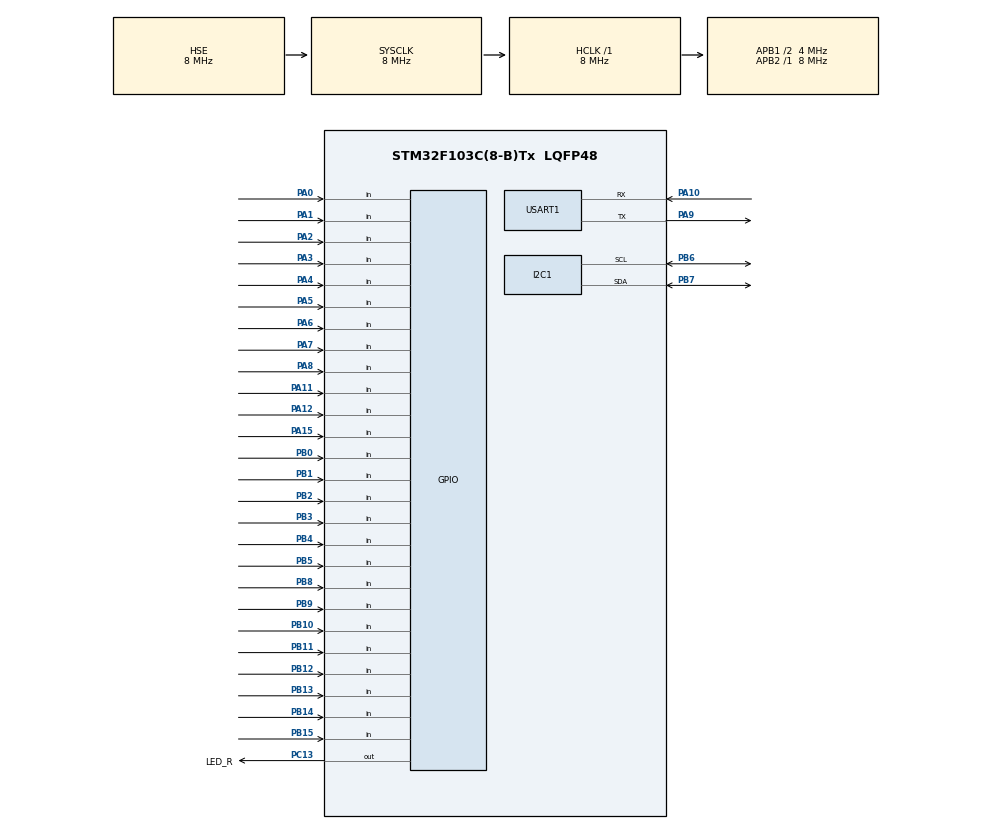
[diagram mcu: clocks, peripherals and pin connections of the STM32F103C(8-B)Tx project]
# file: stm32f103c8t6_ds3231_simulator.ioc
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I2C1.OwnAddress=0x68
IWDG.Prescaler=IWDG_PRESCALER_256
Mcu.Family=STM32F1
Mcu.Name=STM32F103C(8-B)Tx
Mcu.Package=LQFP48
NVIC.I2C1_ER_IRQn=true\:0\:0\:false\:false\:true\:true\:true\:true
NVIC.I2C1_EV_IRQn=true\:0\:0\:false\:false\:true\:true\:true\:true
NVIC.PriorityGroup=NVIC_PRIORITYGROUP_4
NVIC.RTC_IRQn=true\:0\:0\:false\:false\:true\:true\:true\:true
NVIC.USART1_IRQn=true\:0\:0\:false\:false\:true\:true\:true\:true
PA0-WKUP.GPIO_PuPd=GPIO_PULLUP
PA0-WKUP.Signal=GPIO_Input
PA1.GPIO_PuPd=GPIO_PULLUP
PA1.Signal=GPIO_Input
PA10.Mode=Asynchronous
PA10.Signal=USART1_RX
PA11.GPIO_PuPd=GPIO_PULLUP
PA11.Signal=GPIO_Input
PA12.GPIO_PuPd=GPIO_PULLUP
PA12.Signal=GPIO_Input
PA13.Mode=Serial_Wire
PA13.Signal=SYS_JTMS-SWDIO
PA14.Mode=Serial_Wire
PA14.Signal=SYS_JTCK-SWCLK
PA15.GPIO_PuPd=GPIO_PULLUP
PA15.Signal=GPIO_Input
PA2.GPIO_PuPd=GPIO_PULLUP
PA2.Signal=GPIO_Input
PA3.GPIO_PuPd=GPIO_PULLUP
PA3.Signal=GPIO_Input
PA4.GPIO_PuPd=GPIO_PULLUP
PA4.Signal=GPIO_Input
PA5.GPIO_PuPd=GPIO_PULLUP
PA5.Signal=GPIO_Input
PA6.GPIO_PuPd=GPIO_PULLUP
PA6.Signal=GPIO_Input
PA7.GPIO_PuPd=GPIO_PULLUP
PA7.Signal=GPIO_Input
PA8.GPIO_PuPd=GPIO_PULLUP
PA8.Signal=GPIO_Input
PA9.Mode=Asynchronous
PA9.Signal=USART1_TX
PB0.GPIO_PuPd=GPIO_PULLUP
PB0.Signal=GPIO_Input
PB1.GPIO_PuPd=GPIO_PULLUP
PB1.Signal=GPIO_Input
PB10.GPIO_PuPd=GPIO_PULLUP
PB10.Signal=GPIO_Input
PB11.GPIO_PuPd=GPIO_PULLUP
PB11.Signal=GPIO_Input
PB12.GPIO_PuPd=GPIO_PULLUP
PB12.Signal=GPIO_Input
PB13.GPIO_PuPd=GPIO_PULLUP
PB13.Signal=GPIO_Input
PB14.GPIO_PuPd=GPIO_PULLUP
PB14.Signal=GPIO_Input
PB15.GPIO_PuPd=GPIO_PULLUP
PB15.Signal=GPIO_Input
PB2.GPIO_PuPd=GPIO_PULLUP
PB2.Signal=GPIO_Input
PB3.GPIO_PuPd=GPIO_PULLUP
PB3.Signal=GPIO_Input
PB4.GPIO_PuPd=GPIO_PULLUP
PB4.Signal=GPIO_Input
PB5.GPIO_PuPd=GPIO_PULLUP
PB5.Signal=GPIO_Input
PB6.Mode=I2C
PB6.Signal=I2C1_SCL
PB7.Mode=I2C
PB7.Signal=I2C1_SDA
PB8.GPIO_PuPd=GPIO_PULLUP
PB8.Signal=GPIO_Input
PB9.GPIO_PuPd=GPIO_PULLUP
PB9.Signal=GPIO_Input
PC13-TAMPER-RTC.GPIO_Label=LED_R
PC13-TAMPER-RTC.GPIO_PuPd=GPIO_PULLUP
PC13-TAMPER-RTC.GPIO_Speed=GPIO_SPEED_FREQ_HIGH
PC13-TAMPER-RTC.PinState=GPIO_PIN_SET
PC13-TAMPER-RTC.Signal=GPIO_Output
PC14-OSC32_IN.Mode=LSE-External-Oscillator
PC14-OSC32_IN.Signal=RCC_OSC32_IN
PC15-OSC32_OUT.Mode=LSE-External-Oscillator
PC15-OSC32_OUT.Signal=RCC_OSC32_OUT
PD0-OSC_IN.Mode=HSE-External-Oscillator
PD0-OSC_IN.Signal=RCC_OSC_IN
PD1-OSC_OUT.Mode=HSE-External-Oscillator
PD1-OSC_OUT.Signal=RCC_OSC_OUT
ProjectManager.HeapSize=0x200
ProjectManager.StackSize=0x400
ProjectManager.TargetToolchain=MDK-ARM V5
RCC.AHBFreq_Value=8000000
RCC.APB1CLKDivider=RCC_HCLK_DIV2
RCC.APB1Freq_Value=4000000
RCC.APB1TimFreq_Value=8000000
RCC.APB2Freq_Value=8000000
RCC.APB2TimFreq_Value=8000000
RCC.HCLKFreq_Value=8000000
RCC.PLLMUL=RCC_PLL_MUL9
RCC.PLLSourceVirtual=RCC_PLLSOURCE_HSE
RCC.SYSCLKFreq_VALUE=8000000
RCC.SYSCLKSource=RCC_SYSCLKSOURCE_HSE
RCC.USBFreq_Value=48000000
RCC.USBPrescaler=RCC_USBCLKSOURCE_PLL_DIV1_5
RCC.VDD_VALUE=3
USART1.VirtualMode=VM_ASYNC
VP_IWDG_VS_IWDG.Mode=IWDG_Activate
VP_RTC_No_RTC_Output.Mode=RTC_OUT_NO
VP_RTC_VS_RTC_Activate.Mode=RTC_Enabled
VP_RTC_VS_RTC_Calendar.Mode=RTC_Calendar
board=custom

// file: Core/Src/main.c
/* USER CODE BEGIN Header */
/**
  ******************************************************************************
  * @file           : main.c
  * @brief          : Main program body
  ******************************************************************************
  * @attention
  *
  * Copyright (c) 2026 STMicroelectronics.
  * All rights reserved.
  *
  * This software is licensed under terms that can be found in the LICENSE file
  * in the root directory of this software component.
  * If no LICENSE file comes with this software, it is provided AS-IS.
  *
  ******************************************************************************
  */
/* USER CODE END Header */
#include "main.h"
#include "i2c.h"
#include "iwdg.h"
#include "rtc.h"
#include "usart.h"
#include "gpio.h"

/* USER CODE BEGIN Includes */
#include "ds3231_sim.h"
#include "Delay.h"
/* USER CODE END Includes */

void SystemClock_Config(void);

int main(void)
{

  /* MCU Configuration--------------------------------------------------------*/

  /* Reset of all peripherals, Initializes the Flash interface and the Systick. */
  HAL_Init();

  /* Configure the system clock */
  SystemClock_Config();

  /* Initialize all configured peripherals */
  MX_GPIO_Init();
  MX_I2C1_Init();
  MX_RTC_Init();
  MX_USART1_UART_Init();
  MX_IWDG_Init();
  /* USER CODE BEGIN 2 */
  ds3231_sim_init();   /* I2C1 从机 0x68 模拟 DS3231（RTC 日历由 MX_RTC_Init 初始化） */
  /* USER CODE END 2 */

  /* Infinite loop */
  /* USER CODE BEGIN WHILE */
  while (1)
  {
    __WFI();             /* 低功耗：睡眠等待 I2C 从机中断唤醒（从机状态机已根治） */
    ds3231_sim_poll();   /* LED 出错/未连接指示（平时零功耗）+ 应用 RTC 时间写入 */
    ds3231_sim_diag();   /* USART1 诊断（COM4，115200） */
    /* USER CODE END WHILE */

  }
}

void SystemClock_Config(void)
{
  RCC_OscInitTypeDef RCC_OscInitStruct = {0};
  RCC_ClkInitTypeDef RCC_ClkInitStruct = {0};
  RCC_PeriphCLKInitTypeDef PeriphClkInit = {0};

  /** Initializes the RCC Oscillators according to the specified parameters
  * in the RCC_OscInitTypeDef structure.
  */
  RCC_OscInitStruct.OscillatorType = RCC_OSCILLATORTYPE_LSI|RCC_OSCILLATORTYPE_HSE;
  RCC_OscInitStruct.HSEState = RCC_HSE_ON;
  RCC_OscInitStruct.LSIState = RCC_LSI_ON;
  RCC_OscInitStruct.PLL.PLLState = RCC_PLL_NONE;
  if (HAL_RCC_OscConfig(&RCC_OscInitStruct) != HAL_OK)
  {
    Error_Handler();
  }

  /** Initializes the CPU, AHB and APB buses clocks
  */
  RCC_ClkInitStruct.ClockType = RCC_CLOCKTYPE_HCLK|RCC_CLOCKTYPE_SYSCLK
                              |RCC_CLOCKTYPE_PCLK1|RCC_CLOCKTYPE_PCLK2;
  RCC_ClkInitStruct.SYSCLKSource = RCC_SYSCLKSOURCE_HSE;
  RCC_ClkInitStruct.AHBCLKDivider = RCC_SYSCLK_DIV1;
  RCC_ClkInitStruct.APB1CLKDivider = RCC_HCLK_DIV2;
  RCC_ClkInitStruct.APB2CLKDivider = RCC_HCLK_DIV1;

  if (HAL_RCC_ClockConfig(&RCC_ClkInitStruct, FLASH_LATENCY_0) != HAL_OK)
  {
    Error_Handler();
  }
  PeriphClkInit.PeriphClockSelection = RCC_PERIPHCLK_RTC;
  PeriphClkInit.RTCClockSelection = RCC_RTCCLKSOURCE_LSI;
  if (HAL_RCCEx_PeriphCLKConfig(&PeriphClkInit) != HAL_OK)
  {
    Error_Handler();
  }
}

void Error_Handler(void)
{
  __disable_irq();
  while (1)
  {
  }
}
